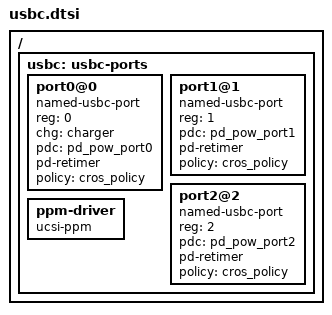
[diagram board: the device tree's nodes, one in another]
/* Copyright 2024 The ChromiumOS Authors
 * Use of this source code is governed by a BSD-style license that can be
 * found in the LICENSE file.
 */

#include <usbc-policy.dtsi>

/ {
	usbc: usbc-ports {
		#address-cells = <1>;
		#size-cells = <0>;

		port0@0 {
			compatible = "named-usbc-port";
			reg = <0>;
			chg = <&charger>;
			pdc = <&pd_pow_port0>;
			pd-retimer;
			policy = <&cros_policy>;
		};
		port1@1 {
			compatible = "named-usbc-port";
			reg = <1>;
			pdc = <&pd_pow_port1>;
			pd-retimer;
			policy = <&cros_policy>;
		};
		port2@2 {
			compatible = "named-usbc-port";
			reg = <2>;
			pdc = <&pd_pow_port2>;
			pd-retimer;
			policy = <&cros_policy>;
		};
		ppm-driver {
			compatible = "ucsi-ppm";
		};
	};
};
